AUTOSAR XML (schema 00048)
standard types defined: uint8, sint16, uint16, uint32, float32
package /Units
  9 x unit:
    Percent: display-name=%
    A: display-name=A
    Nm: display-name=Nm
    V: display-name=V
    W: display-name=W
    degC: display-name=degC
    s: display-name=s
    ms: display-name=ms
    Hz: display-name=Hz
package /Transformers
  data transformation set E2E
    data transformation DcdcOutputP1_Chain: data-transformation-kind=SYMMETRIC, execute-despite-data-unavailability=true, transformer-chain=[ComBased, DcdcOutputP1_E2E]
    data transformation DcdcThermalP2_Chain: data-transformation-kind=SYMMETRIC, execute-despite-data-unavailability=true, transformer-chain=[ComBased, DcdcThermalP2_E2E]
    data transformation DcdcPowerP5_Chain: data-transformation-kind=SYMMETRIC, execute-despite-data-unavailability=true, transformer-chain=[ComBased, DcdcPowerP5_E2E]
    4 x transformation technology, all with buffer-properties={header-length=0, in-place=true}, version=1.0.0:
      ComBased: protocol=COMBased, transformer-class=SERIALIZER
      DcdcOutputP1_E2E: needs-original-data=false, protocol=E2E, end-to-end-transformation-description{counter-offset=8, crc-offset=0, data-id-mode=ALL-16-BIT, max-delta-counter=1, max-no-new-or-repeated-data=15, profile-name=PROFILE_01, sync-counter-init=0}, transformer-class=SAFETY
      DcdcThermalP2_E2E: needs-original-data=false, protocol=E2E, end-to-end-transformation-description{max-delta-counter=1, max-no-new-or-repeated-data=15, offset=0, profile-name=PROFILE_02, sync-counter-init=0}, transformer-class=SAFETY
      DcdcPowerP5_E2E: needs-original-data=false, protocol=E2E, end-to-end-transformation-description{max-delta-counter=1, offset=0, profile-name=PROFILE_05}, transformer-class=SAFETY
package /SecOC
  secure communication props set Profile1
    secure communication authentication props Aes128Cmac24: auth-algorithm=CMAC/AES-128, auth-info-tx-length=24
    secure communication freshness props FreshnessCounter8: freshness-value-length=8, freshness-value-tx-length=8
package /Pdus
  pdu DcdcRail: length=4, contained-i-pdu-props={collection-semantics=LAST-IS-BEST, header-id-short-header=0x100001, trigger=ALWAYS}, transmission-mode-true-timing=cyclic-timing=time-period=0.06, unused-bit-pattern=255  # Contained: the 12 V rail.
    signal OutputVoltage: start 0, 16 bit, little-endian, data-type-policy=OVERRIDE, i-signal-type=PRIMITIVE, base-type=uint16, compu {phys=raw*0.01 for raw 0..65535; unit V}, range phys 0..655.35 V, unit=V, transfer-property=PENDING
    signal OutputCurrent: start 16, 16 bit, little-endian, data-type-policy=OVERRIDE, i-signal-type=PRIMITIVE, base-type=uint16, compu {phys=raw*0.1 for raw 0..65535; unit A}, range phys 0..6553.5 A, unit=A, transfer-property=PENDING
  pdu DcdcInput: length=4, contained-i-pdu-props={collection-semantics=LAST-IS-BEST, header-id-short-header=0x100002, trigger=ALWAYS}, transmission-mode-true-timing=cyclic-timing={time-offset=0.02, time-period=0.06}, unused-bit-pattern=255  # Contained: the pack side.
    signal InputCurrent: start 0, 16 bit, little-endian, data-type-policy=OVERRIDE, i-signal-type=PRIMITIVE, base-type=uint16, compu {phys=raw*0.01 for raw 0..65535; unit A}, range phys 0..655.35 A, unit=A, transfer-property=PENDING
    signal InputVoltage: start 16, 16 bit, little-endian, data-type-policy=OVERRIDE, i-signal-type=PRIMITIVE, base-type=uint16, compu {phys=raw*0.1 for raw 0..65534, 65535=Unknown; unit V}, range phys 0..6553.4 V, unit=V, transfer-property=PENDING
  pdu DcdcHealth: length=4, contained-i-pdu-props={collection-semantics=LAST-IS-BEST, header-id-short-header=0x100003, trigger=ALWAYS}, transmission-mode-true-timing=cyclic-timing={time-offset=0.04, time-period=0.06}, unused-bit-pattern=255  # Contained: temperature, state and uptime.
    signal Temperature: start 0, 8 bit, little-endian, data-type-policy=OVERRIDE, i-signal-type=PRIMITIVE, base-type=uint8, compu {phys=raw-40 for raw 0..255; unit degC}, range phys -40..215 degC, unit=degC, transfer-property=PENDING
    signal DcdcState: start 8, 8 bit, little-endian, data-type-policy=OVERRIDE, i-signal-type=PRIMITIVE, base-type=uint8, compu {0=Idle, 1=Converting, 2=Derating}, transfer-property=PENDING  # Idle: no pack current. Converting. Derating: above 70 degC.
    signal UptimeS: start 16, 16 bit, little-endian, data-type-policy=OVERRIDE, i-signal-type=PRIMITIVE, base-type=uint16, compu {phys=raw for raw 0..65535; unit s}, range phys 0..65535 s, unit=s, transfer-property=PENDING  # Seconds since boot, wrapping.
  pdu DcdcMuxStatic: length=8, unused-bit-pattern=255  # Static part of DcdcMux.
    signal DcdcState: start 8, 8 bit, little-endian, data-type-policy=OVERRIDE, i-signal-type=PRIMITIVE, base-type=uint8, compu {0=Idle, 1=Converting, 2=Derating}, transfer-property=PENDING  # Idle: no pack current. Converting. Derating: above 70 degC.
    signal OutputVoltage: start 16, 16 bit, little-endian, data-type-policy=OVERRIDE, i-signal-type=PRIMITIVE, base-type=uint16, compu {phys=raw*0.01 for raw 0..65535; unit V}, range phys 0..655.35 V, unit=V, transfer-property=PENDING
  pdu DcdcMuxCurrents: length=8, transmission-mode-true-timing=cyclic-timing=time-period=0.1, unused-bit-pattern=255  # DcdcMux dynamic part, selector 0.
    signal DcdcMuxSelector: start 0, 8 bit, little-endian, data-type-policy=OVERRIDE, i-signal-type=PRIMITIVE, base-type=uint8, compu {0=Currents, 1=Limits}, transfer-property=PENDING  # Selects the dynamic part.
    signal OutputCurrent: start 32, 16 bit, little-endian, data-type-policy=OVERRIDE, i-signal-type=PRIMITIVE, base-type=uint16, compu {phys=raw*0.1 for raw 0..65535; unit A}, range phys 0..6553.5 A, unit=A, transfer-property=PENDING
    signal InputCurrent: start 48, 16 bit, little-endian, data-type-policy=OVERRIDE, i-signal-type=PRIMITIVE, base-type=uint16, compu {phys=raw*0.01 for raw 0..65535; unit A}, range phys 0..655.35 A, unit=A, transfer-property=PENDING
  pdu DcdcMuxLimits: length=8, transmission-mode-true-timing=cyclic-timing={time-offset=0.05, time-period=0.1}, unused-bit-pattern=255  # DcdcMux dynamic part, selector 1.
    signal DcdcMuxSelector: start 0, 8 bit, little-endian, data-type-policy=OVERRIDE, i-signal-type=PRIMITIVE, base-type=uint8, compu {0=Currents, 1=Limits}, transfer-property=PENDING  # Selects the dynamic part.
    signal AuxCurrentLimit: start 32, 16 bit, little-endian, data-type-policy=OVERRIDE, i-signal-type=PRIMITIVE, base-type=uint16, compu {phys=raw*0.01 for raw 0..65535; unit A}, range phys 0..655.35 A, unit=A, transfer-property=PENDING
    signal SetpointVoltage: start 48, 16 bit, little-endian, data-type-policy=OVERRIDE, i-signal-type=PRIMITIVE, base-type=uint16, compu {phys=raw*0.01 for raw 0..65535; unit V}, range phys 0..655.35 V, unit=V, transfer-property=PENDING
  pdu DcdcSecuredPayload: length=4, transmission-mode-true-timing=cyclic-timing=time-period=0.1, unused-bit-pattern=255  # Authentic PDU of DcdcSecured.
    signal OutputVoltage: start 0, 16 bit, little-endian, data-type-policy=OVERRIDE, i-signal-type=PRIMITIVE, base-type=uint16, compu {phys=raw*0.01 for raw 0..65535; unit V}, range phys 0..655.35 V, unit=V, transfer-property=PENDING
    signal InputCurrent: start 16, 16 bit, little-endian, data-type-policy=OVERRIDE, i-signal-type=PRIMITIVE, base-type=uint16, compu {phys=raw*0.01 for raw 0..65535; unit A}, range phys 0..655.35 A, unit=A, transfer-property=PENDING
  dcm i pdu UdsRequestSdu: length=1026, diag-pdu-type=DIAG-REQUEST  # Physically addressed diagnostic requests.
  dcm i pdu UdsFunctionalRequestSdu: length=1026, diag-pdu-type=DIAG-REQUEST  # Functionally addressed diagnostic requests (single frames).
  dcm i pdu UdsResponseSdu: length=1026, diag-pdu-type=DIAG-RESPONSE  # Diagnostic responses.
package /Signals/DcdcOutputP1
  i signal group DcdcOutputP1_E2E: com-based-signal-group-transformations=DcdcOutputP1_Chain, i-signal=[DcdcOutputP1/CRC, DcdcOutputP1/Counter, DcdcOutputP1/DcdcState, DcdcOutputP1/OutputVoltage, DcdcOutputP1/OutputCurrent, DcdcOutputP1/InputCurrent], system-signal-group=DcdcOutputP1_E2E, end-to-end-transformation-i-signal-props{transformer=DcdcOutputP1_E2E, data-ids=0x0310, data-length=64}
package /Signals/DcdcThermalP2
  i signal group DcdcThermalP2_E2E:
    com-based-signal-group-transformations=DcdcThermalP2_Chain
    i-signal=[DcdcThermalP2/CRC, DcdcThermalP2/Counter, DcdcThermalP2/Temperature, DcdcThermalP2/DerateActive, DcdcThermalP2/AuxCurrentLimit]
    system-signal-group=DcdcThermalP2_E2E
    end-to-end-transformation-i-signal-props{transformer=DcdcThermalP2_E2E, data-ids=[0x30, 0x31, 0x32, 0x33, 0x34, 0x35, 0x36, 0x37, 0x38, 0x39, 0x3A, 0x3B, 0x3C, 0x3D, 0x3E, 0x3F], data-length=64}
package /Signals/DcdcPowerP5
  i signal group DcdcPowerP5_E2E: com-based-signal-group-transformations=DcdcPowerP5_Chain, i-signal=[DcdcPowerP5/CRC, DcdcPowerP5/Counter, OutputPower, DcdcPowerP5/InputVoltage, DcdcPowerP5/SetpointVoltage], system-signal-group=DcdcPowerP5_E2E, end-to-end-transformation-i-signal-props{transformer=DcdcPowerP5_E2E, data-ids=0x0312, data-length=64}
package /PduGroups
  8 x i signal i pdu group:
    BMS_Rx: communication-direction=IN, i-signal-i-pdus=[VCU_Command, DCDC_Status]
    BMS_Tx: communication-direction=OUT, i-signal-i-pdus=[BMS_Status, BMS_Limits, BMS_CellVoltages]
    DCDC_Rx: communication-direction=IN, i-signal-i-pdus=[VCU_Command, BMS_Status, BMS_Limits]
    DCDC_Tx: communication-direction=OUT
      i-signal-i-pdus:
        DCDC_Status
        DcdcOutputP1
        DcdcThermalP2
        DcdcPowerP5
        DcdcRail
        DcdcInput
        DcdcHealth
        DcdcMuxStatic
        DcdcMuxCurrents
        DcdcMuxLimits
        DcdcSecuredPayload
    SIG_Tx: communication-direction=OUT, i-signal-i-pdus=Waveform
    Tester_Rx: communication-direction=IN
      i-signal-i-pdus:
        DcdcOutputP1
        DcdcThermalP2
        DcdcPowerP5
        DcdcRail
        DcdcInput
        DcdcHealth
        DcdcMuxStatic
        DcdcMuxCurrents
        DcdcMuxLimits
        DcdcSecuredPayload
    VCU_Rx: communication-direction=IN, i-signal-i-pdus=[BMS_Status, BMS_Limits, BMS_CellVoltages, DCDC_Status, Waveform]
    VCU_Tx: communication-direction=OUT, i-signal-i-pdus=VCU_Command
package /Ecus
  5 x ecu instance:
    VCU: associated-com-i-pdu-group=[VCU_Rx, VCU_Tx]  # Vehicle control unit. Commands the operating mode and carries the bus heartbeat.
      can communication controller VCU_CanController
      can communication connector VCU_CanConnector: comm-controller=VCU_CanController
    BMS: associated-com-i-pdu-group=[BMS_Rx, BMS_Tx]  # Battery management system. Reports pack state and publishes the current limits the DC-DC must respect.
      can communication controller BMS_CanController
      can communication connector BMS_CanConnector: comm-controller=BMS_CanController
    DCDC: associated-com-i-pdu-group=[DCDC_Rx, DCDC_Tx]  # DC-DC converter. Steps the high-voltage pack down to the 12 V rail, within the BMS current limit. AUTOSAR PDUs (E2E, container, multiplexed, secured), UDS on CanTp, XCP on CAN. SOME/IP DcdcService and DoIP on BenchEth.
      can communication controller DCDC_CanController
      ethernet communication controller DCDC_EthController
      can communication connector DCDC_CanConnector: comm-controller=DCDC_CanController
      ethernet communication connector DCDC_EthConnector: comm-controller=DCDC_EthController
    SIG: associated-com-i-pdu-group=SIG_Tx
      can communication controller SIG_CanController
      can communication connector SIG_CanConnector: comm-controller=SIG_CanController
    Tester: associated-com-i-pdu-group=Tester_Rx  # Diagnostic tester, XCP master and logger on the bus.
      can communication controller Tester_CanController
      can communication connector Tester_CanConnector: comm-controller=Tester_CanController
package /Communication
  can cluster CanFull: baudrate=500000, protocol-name=CAN, protocol-version=2.0  # The can-full bench bus: classic CAN, 500 kbit/s, 11-bit identifiers.
    can physical channel CanFullChannel: comm-connectors=[VCU_CanConnector, BMS_CanConnector, DCDC_CanConnector, SIG_CanConnector, Tester_CanConnector]
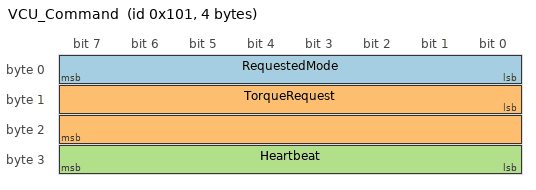
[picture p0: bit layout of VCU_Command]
      frame VCU_Command: id 0x101, from VCU, to BMS DCDC, frame-length=4, can-addressing-mode=STANDARD, can-frame-rx-behavior=CAN-20, can-frame-tx-behavior=CAN-20  # Operating mode request and heartbeat. The BMS and DC-DC both follow the commanded mode.
        pdu VCU_Command: length=4, transmission-mode-true-timing=cyclic-timing=time-period=0.1, unused-bit-pattern=0  # Operating mode request and heartbeat. The BMS and DC-DC both follow the commanded mode.
          signal RequestedMode: start 0, 8 bit, little-endian, data-type-policy=OVERRIDE, i-signal-type=PRIMITIVE, base-type=uint8, compu {0=Standby, 1=Drive, 2=Charge, 3=Fault}, transfer-property=PENDING
          signal TorqueRequest: start 8, 16 bit, little-endian, data-type-policy=OVERRIDE, i-signal-type=PRIMITIVE, base-type=sint16, compu {phys=raw*0.1 for raw -10000..10000; unit Nm}, range phys -1000..1000 Nm, unit=Nm, transfer-property=PENDING  # Positive is drive, negative is regenerative braking.
          signal Heartbeat: start 24, 8 bit, little-endian, data-type-policy=OVERRIDE, i-signal-type=PRIMITIVE, base-type=uint8, compu {phys=raw for raw 0..255}, range phys 0..255, transfer-property=PENDING
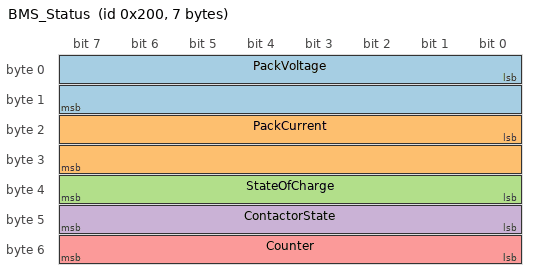
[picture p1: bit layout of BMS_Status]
      frame BMS_Status: id 0x200, from BMS, to VCU DCDC, frame-length=7, can-addressing-mode=STANDARD, can-frame-rx-behavior=CAN-20, can-frame-tx-behavior=CAN-20  # Pack-level measurements and contactor state.
        pdu BMS_Status: length=7, transmission-mode-true-timing=cyclic-timing=time-period=0.1, unused-bit-pattern=0  # Pack-level measurements and contactor state.
          signal PackVoltage: start 0, 16 bit, little-endian, data-type-policy=OVERRIDE, i-signal-type=PRIMITIVE, base-type=uint16, compu {phys=raw*0.1 for raw 0..10000; unit V}, range phys 0..1000 V, unit=V, transfer-property=PENDING
          signal PackCurrent: start 16, 16 bit, little-endian, data-type-policy=OVERRIDE, i-signal-type=PRIMITIVE, base-type=sint16, compu {phys=raw*0.1 for raw -10000..10000; unit A}, range phys -1000..1000 A, unit=A, transfer-property=PENDING  # Positive is discharge, negative is charge.
          signal StateOfCharge: start 32, 8 bit, little-endian, data-type-policy=OVERRIDE, i-signal-type=PRIMITIVE, base-type=uint8, compu {phys=raw*0.5 for raw 0..200; unit %}, range phys 0..100 %, unit=%, transfer-property=PENDING
          signal ContactorState: start 40, 8 bit, little-endian, data-type-policy=OVERRIDE, i-signal-type=PRIMITIVE, base-type=uint8, compu {0=Open, 1=Precharge, 2=Closed, 3=Fault}, transfer-property=PENDING
          signal Counter: start 48, 8 bit, little-endian, data-type-policy=OVERRIDE, i-signal-type=PRIMITIVE, base-type=uint8, compu {phys=raw for raw 0..255}, range phys 0..255, transfer-property=PENDING
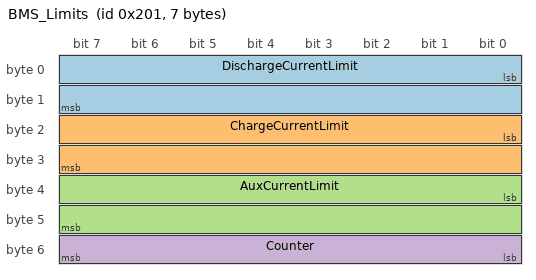
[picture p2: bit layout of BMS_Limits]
      frame BMS_Limits: id 0x201, from BMS, to VCU DCDC, frame-length=7, can-addressing-mode=STANDARD, can-frame-rx-behavior=CAN-20, can-frame-tx-behavior=CAN-20  # The current envelope the pack allows right now. AuxCurrentLimit bounds what the DC-DC may draw from the pack.
        pdu BMS_Limits: length=7, transmission-mode-true-timing=cyclic-timing=time-period=0.1, unused-bit-pattern=0  # The current envelope the pack allows right now. AuxCurrentLimit bounds what the DC-DC may draw from the pack.
          signal DischargeCurrentLimit: start 0, 16 bit, little-endian, data-type-policy=OVERRIDE, i-signal-type=PRIMITIVE, base-type=uint16, compu {phys=raw*0.01 for raw 0..65535; unit A}, range phys 0..655.35 A, unit=A, transfer-property=PENDING  # Pack-level ceiling for traction draw.
          signal ChargeCurrentLimit: start 16, 16 bit, little-endian, data-type-policy=OVERRIDE, i-signal-type=PRIMITIVE, base-type=uint16, compu {phys=raw*0.01 for raw 0..65535; unit A}, range phys 0..655.35 A, unit=A, transfer-property=PENDING
          signal AuxCurrentLimit: start 32, 16 bit, little-endian, data-type-policy=OVERRIDE, i-signal-type=PRIMITIVE, base-type=uint16, compu {phys=raw*0.01 for raw 0..65535; unit A}, range phys 0..655.35 A, unit=A, transfer-property=PENDING  # Pack current the DC-DC converter may draw. The BMS reduces it while charging.
          signal Counter: start 48, 8 bit, little-endian, data-type-policy=OVERRIDE, i-signal-type=PRIMITIVE, base-type=uint8, compu {phys=raw for raw 0..255}, range phys 0..255, transfer-property=PENDING
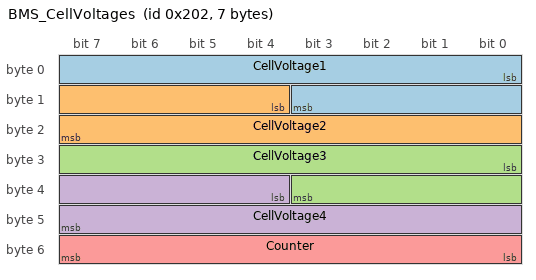
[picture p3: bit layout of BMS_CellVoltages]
      frame BMS_CellVoltages: id 0x202, from BMS, to VCU, frame-length=7, can-addressing-mode=STANDARD, can-frame-rx-behavior=CAN-20, can-frame-tx-behavior=CAN-20  # Per-cell voltages. Four cells, one frame, no multiplexing.
        pdu BMS_CellVoltages: length=7, transmission-mode-true-timing=cyclic-timing=time-period=0.5, unused-bit-pattern=0  # Per-cell voltages. Four cells, one frame, no multiplexing.
          signal CellVoltage1: start 0, 12 bit, little-endian, data-type-policy=OVERRIDE, i-signal-type=PRIMITIVE, base-type=uint16, compu {phys=raw*0.001+2 for raw 0..4095; unit V}, range phys 2..6.095 V, unit=V, transfer-property=PENDING
          signal CellVoltage2: start 12, 12 bit, little-endian, data-type-policy=OVERRIDE, i-signal-type=PRIMITIVE, base-type=uint16, compu {phys=raw*0.001+2 for raw 0..4095; unit V}, range phys 2..6.095 V, unit=V, transfer-property=PENDING
          signal CellVoltage3: start 24, 12 bit, little-endian, data-type-policy=OVERRIDE, i-signal-type=PRIMITIVE, base-type=uint16, compu {phys=raw*0.001+2 for raw 0..4095; unit V}, range phys 2..6.095 V, unit=V, transfer-property=PENDING
          signal CellVoltage4: start 36, 12 bit, little-endian, data-type-policy=OVERRIDE, i-signal-type=PRIMITIVE, base-type=uint16, compu {phys=raw*0.001+2 for raw 0..4095; unit V}, range phys 2..6.095 V, unit=V, transfer-property=PENDING
          signal Counter: start 48, 8 bit, little-endian, data-type-policy=OVERRIDE, i-signal-type=PRIMITIVE, base-type=uint8, compu {phys=raw for raw 0..255}, range phys 0..255, transfer-property=PENDING
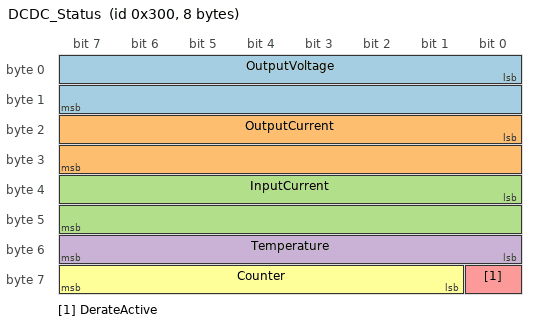
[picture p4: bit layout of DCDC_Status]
      frame DCDC_Status: id 0x300, from DCDC, to VCU BMS, frame-length=8, can-addressing-mode=STANDARD, can-frame-rx-behavior=CAN-20, can-frame-tx-behavior=CAN-20  # DC-DC converter state. InputCurrent is drawn from the pack and must stay within BMS_Limits.AuxCurrentLimit.
        pdu DCDC_Status: length=8, transmission-mode-true-timing=cyclic-timing=time-period=0.05, unused-bit-pattern=0  # DC-DC converter state. InputCurrent is drawn from the pack and must stay within BMS_Limits.AuxCurrentLimit.
          signal OutputVoltage: start 0, 16 bit, little-endian, data-type-policy=OVERRIDE, i-signal-type=PRIMITIVE, base-type=uint16, compu {phys=raw*0.01 for raw 0..65535; unit V}, range phys 0..655.35 V, unit=V, transfer-property=PENDING
          signal OutputCurrent: start 16, 16 bit, little-endian, data-type-policy=OVERRIDE, i-signal-type=PRIMITIVE, base-type=uint16, compu {phys=raw*0.1 for raw 0..65535; unit A}, range phys 0..6553.5 A, unit=A, transfer-property=PENDING
          signal InputCurrent: start 32, 16 bit, little-endian, data-type-policy=OVERRIDE, i-signal-type=PRIMITIVE, base-type=uint16, compu {phys=raw*0.01 for raw 0..65535; unit A}, range phys 0..655.35 A, unit=A, transfer-property=PENDING  # Current drawn from the high-voltage pack.
          signal Temperature: start 48, 8 bit, little-endian, data-type-policy=OVERRIDE, i-signal-type=PRIMITIVE, base-type=uint8, compu {phys=raw-40 for raw 0..255; unit degC}, range phys -40..215 degC, unit=degC, transfer-property=PENDING
          signal DerateActive: start 56, 1 bit, little-endian, data-type-policy=OVERRIDE, i-signal-type=PRIMITIVE, base-type=uint8, compu {0=Inactive, 1=Active}, transfer-property=PENDING  # Set when the converter is limiting output because of temperature.
          signal Counter: start 57, 7 bit, little-endian, data-type-policy=OVERRIDE, i-signal-type=PRIMITIVE, base-type=uint8, compu {phys=raw for raw 0..127}, range phys 0..127, transfer-property=PENDING
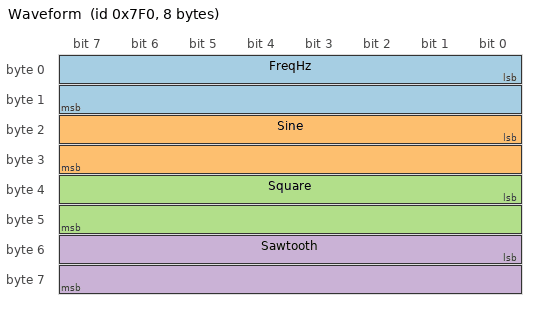
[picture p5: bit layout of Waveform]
      frame Waveform: id 0x7F0, from SIG, to VCU, frame-length=8, can-addressing-mode=STANDARD, can-frame-rx-behavior=CAN-20, can-frame-tx-behavior=CAN-20  # Signal generator: one phase, chirped 1 to 100 Hz over 20 s, as sine, square and sawtooth. Lowest-priority ID on the bus.
        pdu Waveform: length=8, transmission-mode-true-timing=cyclic-timing=time-period=0.002, unused-bit-pattern=0  # Signal generator: one phase, chirped 1 to 100 Hz over 20 s, as sine, square and sawtooth. Lowest-priority ID on the bus.
          signal FreqHz: start 0, 16 bit, little-endian, data-type-policy=OVERRIDE, i-signal-type=PRIMITIVE, base-type=uint16, compu {phys=raw*0.01 for raw 0..65535; unit Hz}, range phys 0..655.35 Hz, unit=Hz, transfer-property=PENDING
          signal Sine: start 16, 16 bit, little-endian, data-type-policy=OVERRIDE, i-signal-type=PRIMITIVE, base-type=sint16, compu {phys=raw*0.001 for raw -1000..1000}, range phys -1..1, transfer-property=PENDING
          signal Square: start 32, 16 bit, little-endian, data-type-policy=OVERRIDE, i-signal-type=PRIMITIVE, base-type=sint16, compu {phys=raw*0.001 for raw -1000..1000}, range phys -1..1, transfer-property=PENDING
          signal Sawtooth: start 48, 16 bit, little-endian, data-type-policy=OVERRIDE, i-signal-type=PRIMITIVE, base-type=sint16, compu {phys=raw*0.001 for raw -1000..1000}, range phys -1..1, transfer-property=PENDING
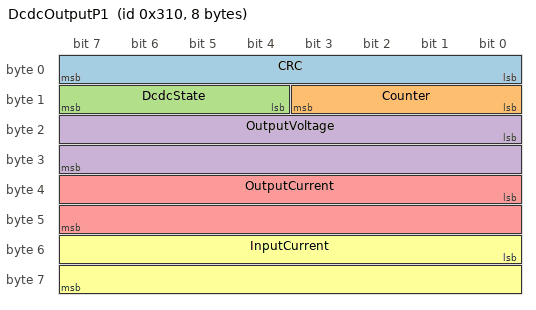
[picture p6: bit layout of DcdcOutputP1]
      frame DcdcOutputP1: id 0x310, from DCDC, to Tester, frame-length=8, can-addressing-mode=STANDARD, can-frame-rx-behavior=CAN-20, can-frame-tx-behavior=CAN-20  # Rail output and pack current, E2E profile 1.
        pdu DcdcOutputP1: length=8, transmission-mode-true-timing=cyclic-timing=time-period=0.02, unused-bit-pattern=255  # Rail output and pack current, E2E profile 1.
          signal CRC: start 0, 8 bit, little-endian, data-type-policy=OVERRIDE, i-signal-type=PRIMITIVE, base-type=uint8, transfer-property=PENDING  # E2E CRC
          signal Counter: start 8, 4 bit, little-endian, data-type-policy=OVERRIDE, i-signal-type=PRIMITIVE, base-type=uint8, transfer-property=PENDING  # E2E counter
          signal DcdcState: start 12, 4 bit, little-endian, data-type-policy=OVERRIDE, i-signal-type=PRIMITIVE, base-type=uint8, compu {0=Idle, 1=Converting, 2=Derating}, transfer-property=PENDING  # Idle: no pack current. Converting. Derating: above 70 degC.
          signal OutputVoltage: start 16, 16 bit, little-endian, data-type-policy=OVERRIDE, i-signal-type=PRIMITIVE, base-type=uint16, compu {phys=raw*0.001 for raw 0..65535; unit V}, range phys 0..65.535 V, unit=V, transfer-property=PENDING
          signal OutputCurrent: start 32, 16 bit, little-endian, data-type-policy=OVERRIDE, i-signal-type=PRIMITIVE, base-type=uint16, compu {phys=raw*0.05 for raw 0..65535; unit A}, range phys 0..3276.75 A, unit=A, transfer-property=PENDING
          signal InputCurrent: start 48, 16 bit, little-endian, data-type-policy=OVERRIDE, i-signal-type=PRIMITIVE, base-type=uint16, compu {phys=raw*0.001 for raw 0..65535; unit A}, range phys 0..65.535 A, unit=A, transfer-property=PENDING  # Current drawn from the high-voltage pack.
          mapping DcdcOutputP1_E2E: i-signal-group=DcdcOutputP1_E2E
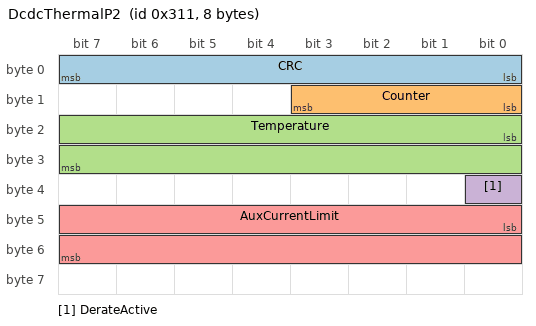
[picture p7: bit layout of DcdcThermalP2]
      frame DcdcThermalP2: id 0x311, from DCDC, to Tester, frame-length=8, can-addressing-mode=STANDARD, can-frame-rx-behavior=CAN-20, can-frame-tx-behavior=CAN-20  # Thermal state and the pack allowance, E2E profile 2.
        pdu DcdcThermalP2: length=8, transmission-mode-true-timing=cyclic-timing=time-period=0.05, unused-bit-pattern=255  # Thermal state and the pack allowance, E2E profile 2.
          signal CRC: start 0, 8 bit, little-endian, data-type-policy=OVERRIDE, i-signal-type=PRIMITIVE, base-type=uint8, transfer-property=PENDING  # E2E CRC
          signal Counter: start 8, 4 bit, little-endian, data-type-policy=OVERRIDE, i-signal-type=PRIMITIVE, base-type=uint8, transfer-property=PENDING  # E2E counter
          signal Temperature: start 16, 16 bit, little-endian, data-type-policy=OVERRIDE, i-signal-type=PRIMITIVE, base-type=sint16, compu {phys=raw*0.1 for raw -400..2150; unit degC}, range phys -40..215 degC, unit=degC, transfer-property=PENDING
          signal DerateActive: start 32, 1 bit, little-endian, data-type-policy=OVERRIDE, i-signal-type=PRIMITIVE, base-type=uint8, compu {0=Inactive, 1=Active}, transfer-property=PENDING  # Set while the converter limits its output for temperature.
          signal AuxCurrentLimit: start 40, 16 bit, little-endian, data-type-policy=OVERRIDE, i-signal-type=PRIMITIVE, base-type=uint16, compu {phys=raw*0.01 for raw 0..65535; unit A}, range phys 0..655.35 A, unit=A, transfer-property=PENDING  # BMS_Limits.AuxCurrentLimit as the converter follows it.
          mapping DcdcThermalP2_E2E: i-signal-group=DcdcThermalP2_E2E
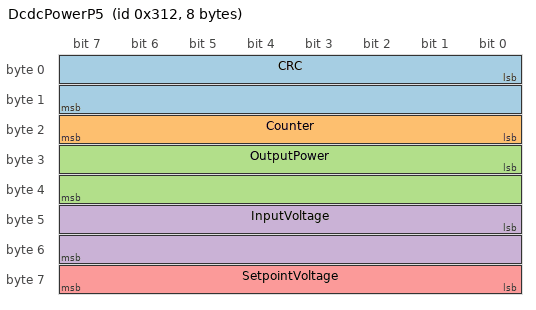
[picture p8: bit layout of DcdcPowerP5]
      frame DcdcPowerP5: id 0x312, from DCDC, to Tester, frame-length=8, can-addressing-mode=STANDARD, can-frame-rx-behavior=CAN-20, can-frame-tx-behavior=CAN-20  # Power, pack voltage and setpoint, E2E profile 5.
        pdu DcdcPowerP5: length=8, transmission-mode-true-timing=cyclic-timing=time-period=0.02, unused-bit-pattern=255  # Power, pack voltage and setpoint, E2E profile 5.
          signal CRC: start 0, 16 bit, little-endian, data-type-policy=OVERRIDE, i-signal-type=PRIMITIVE, base-type=uint16, transfer-property=PENDING  # E2E CRC
          signal Counter: start 16, 8 bit, little-endian, data-type-policy=OVERRIDE, i-signal-type=PRIMITIVE, base-type=uint8, transfer-property=PENDING  # E2E counter
          signal OutputPower: start 24, 16 bit, little-endian, data-type-policy=OVERRIDE, i-signal-type=PRIMITIVE, base-type=uint16, compu {phys=raw for raw 0..65535; unit W}, range phys 0..65535 W, unit=W, transfer-property=PENDING  # Rail voltage times rail current.
          signal InputVoltage: start 40, 16 bit, little-endian, data-type-policy=OVERRIDE, i-signal-type=PRIMITIVE, base-type=uint16, compu {phys=raw*0.1 for raw 0..65534, 65535=Unknown; unit V}, range phys 0..6553.4 V, unit=V, transfer-property=PENDING  # Pack voltage from BMS_Status; Unknown when none is fresh.
          signal SetpointVoltage: start 56, 8 bit, little-endian, data-type-policy=OVERRIDE, i-signal-type=PRIMITIVE, base-type=uint8, compu {phys=raw*0.1 for raw 0..255; unit V}, range phys 0..25.5 V, unit=V, transfer-property=PENDING  # Output voltage the converter regulates to.
          mapping DcdcPowerP5_E2E: i-signal-group=DcdcPowerP5_E2E
      frame DcdcContainer: id 0x313, from DCDC, to Tester, frame-length=8, can-addressing-mode=STANDARD, can-frame-rx-behavior=CAN-20, can-frame-tx-behavior=CAN-20  # Dynamic container, short headers: one contained PDU per frame.
        container i pdu DcdcContainer: length=8, contained-pdu-triggering=[PT_DcdcRail, PT_DcdcInput, PT_DcdcHealth], container-trigger=FIRST-CONTAINED-TRIGGER, header-type=SHORT-HEADER, unused-bit-pattern=255  # Dynamic container, short headers: one contained PDU per frame.
      frame DcdcMux: id 0x314, from DCDC, to Tester, frame-length=8, can-addressing-mode=STANDARD, can-frame-rx-behavior=CAN-20, can-frame-tx-behavior=CAN-20  # Multiplexed: state and voltage always, currents and limits in turn.
        multiplexed i pdu DcdcMux:  # Multiplexed: state and voltage always, currents and limits in turn.
          length=8
          dynamic-part{segment-positions=[{segment-byte-order=little-endian, segment-length=8, segment-position=0}, {segment-byte-order=little-endian, segment-length=32, segment-position=32}], dynamic-part-alternatives=[{i-pdu=DcdcMuxCurrents, initial-dynamic-part=true, selector-field-code=0}, {i-pdu=DcdcMuxLimits, initial-dynamic-part=false, selector-field-code=1}]}
          selector-field-byte-order=little-endian
          selector-field-length=8
          selector-field-start-position=0
          static-part{segment-position{segment-byte-order=little-endian, segment-length=24, segment-position=8}, i-pdu=DcdcMuxStatic}
          trigger-mode=DYNAMIC-PART-TRIGGER
          unused-bit-pattern=255
      frame DcdcSecured: id 0x315, from DCDC, to Tester, frame-length=8, can-addressing-mode=STANDARD, can-frame-rx-behavior=CAN-20, can-frame-tx-behavior=CAN-20  # SecOC profile 1 (24Bit-CMAC-8Bit-FV): payload, 8-bit freshness, 24-bit AES-128 CMAC.
        secured i pdu DcdcSecured: length=8, authentication-props=Aes128Cmac24, freshness-props=FreshnessCounter8, payload=PT_DcdcSecuredPayload, secure-communication-props=data-id=0x0315  # SecOC profile 1 (24Bit-CMAC-8Bit-FV): payload, 8-bit freshness, 24-bit AES-128 CMAC.
      frame UdsRequest: id 0x7E0, from Tester, to DCDC, frame-length=8, can-addressing-mode=STANDARD, can-frame-rx-behavior=CAN-20, can-frame-tx-behavior=CAN-20  # ISO-TP frames of physical requests, and the tester's flow control.
        n pdu UdsRequest: length=8  # ISO-TP frames of physical requests, and the tester's flow control.
      frame UdsFunctionalRequest: id 0x7DF, from Tester, to DCDC, frame-length=8, can-addressing-mode=STANDARD, can-frame-rx-behavior=CAN-20, can-frame-tx-behavior=CAN-20  # ISO-TP single frames of functional requests.
        n pdu UdsFunctionalRequest: length=8  # ISO-TP single frames of functional requests.
      frame UdsResponse: id 0x7E8, from DCDC, to Tester, frame-length=8, can-addressing-mode=STANDARD, can-frame-rx-behavior=CAN-20, can-frame-tx-behavior=CAN-20  # ISO-TP frames of responses, and the DC-DC's flow control.
        n pdu UdsResponse: length=8  # ISO-TP frames of responses, and the DC-DC's flow control.
      frame XcpCro: id 0x6F0, from Tester, to DCDC, frame-length=8, can-addressing-mode=STANDARD, can-frame-rx-behavior=CAN-20, can-frame-tx-behavior=CAN-20  # XCP master to slave.
        general purpose i pdu XcpCro: category=XCP, length=8  # XCP master to slave.
      frame XcpDto: id 0x6F1, from DCDC, to Tester, frame-length=8, can-addressing-mode=STANDARD, can-frame-rx-behavior=CAN-20, can-frame-tx-behavior=CAN-20  # XCP slave to master: responses, events, DAQ.
        general purpose i pdu XcpDto: category=XCP, length=8  # XCP slave to master: responses, events, DAQ.
      pdu triggering PT_DcdcRail: pdu=DcdcRail, from DCDC, to Tester
      pdu triggering PT_DcdcInput: pdu=DcdcInput, from DCDC, to Tester
      pdu triggering PT_DcdcHealth: pdu=DcdcHealth, from DCDC, to Tester
      pdu triggering PT_DcdcMuxStatic: pdu=DcdcMuxStatic, from DCDC, to Tester
      pdu triggering PT_DcdcMuxCurrents: pdu=DcdcMuxCurrents, from DCDC, to Tester
      pdu triggering PT_DcdcMuxLimits: pdu=DcdcMuxLimits, from DCDC, to Tester
      pdu triggering PT_DcdcSecuredPayload: pdu=DcdcSecuredPayload, from DCDC, to Tester
      pdu triggering PT_UdsRequestSdu: pdu=UdsRequestSdu, from Tester, to DCDC
      pdu triggering PT_UdsFunctionalRequestSdu: pdu=UdsFunctionalRequestSdu, from Tester, to DCDC
      pdu triggering PT_UdsResponseSdu: pdu=UdsResponseSdu, from DCDC, to Tester
  ethernet cluster BenchEth  # The bench Ethernet: the DC-DC at 10.1.1.75/24, SOME/IP on UDP only, SD on UDP 30490 and multicast group 224.224.224.245.
    ethernet physical channel BenchEthCh: comm-connectors=DCDC_EthConnector
      network endpoint NE_Dcdc: network-endpoint-addresses=ipv-4-configuration={ipv-4-address=10.1.1.75, ipv-4-address-source=FIXED, network-mask=255.255.255.0}
      network endpoint NE_SdMulticast: network-endpoint-addresses=ipv-4-configuration={ipv-4-address=224.224.224.245, ipv-4-address-source=FIXED}
      so-ad-config:
        socket address SA_DcdcService: connector=DCDC_EthConnector
          application endpoint SA_DcdcService_AE: network-endpoint=NE_Dcdc, tp-configuration=udp-tp=udp-tp-port=port-number=30509
        socket address SA_Sd: multicast-connector=DCDC_EthConnector
          application endpoint SA_Sd_AE: network-endpoint=NE_SdMulticast, tp-configuration=udp-tp=udp-tp-port=port-number=30490
package /CanTp
  can tp config CanFullCanTp: communication-cluster=CanFull, tp-ecus=[DCDC, Tester]  # ISO 15765-2 normal addressing, as the DC-DC's UDS server runs it: block size 0, STmin 0, frames padded to 8 bytes (0xCC), N_As/N_Ar/N_Bs/N_Cr 1 s, half duplex.
    can tp channel UdsChannel: channel-id=0, channel-mode=HALF-DUPLEX-MODE
    can-tp-connection addressing-format=STANDARD, can-tp-channel=UdsChannel, data-pdu=UdsRequest, flow-control-pdu=UdsResponse, max-block-size=0, padding-activation=true, receiver=DCDC_TpNode, ta-type=PHYSICAL, timeout-bs=1, timeout-cr=1, tp-sdu=UdsRequestSdu, transmitter=Tester_TpNode:
      ident UdsPhysical
    can-tp-connection addressing-format=STANDARD, can-tp-channel=UdsChannel, data-pdu=UdsFunctionalRequest, max-block-size=0, padding-activation=true, receiver=DCDC_TpNode, ta-type=FUNCTIONAL, tp-sdu=UdsFunctionalRequestSdu, transmitter=Tester_TpNode:
      ident UdsFunctional
    can-tp-connection addressing-format=STANDARD, can-tp-channel=UdsChannel, data-pdu=UdsResponse, flow-control-pdu=UdsRequest, max-block-size=0, padding-activation=true, receiver=Tester_TpNode, ta-type=PHYSICAL, timeout-bs=1, timeout-cr=1, tp-sdu=UdsResponseSdu, transmitter=DCDC_TpNode:
      ident UdsResponse
    can tp node DCDC_TpNode: connector=DCDC_CanConnector, max-fc-wait=0, st-min=0, timeout-ar=1, timeout-as=1
    can tp node Tester_TpNode: connector=Tester_CanConnector, max-fc-wait=0, st-min=0, timeout-ar=1, timeout-as=1
package /DataTypes
  impl type DcdcStatusType: category=STRUCTURE  # 26 bytes. InputVoltage is NaN with no fresh BMS_Status; Counter is the DCDC_Status Counter of the same sample.
    8 x element, all with category=VALUE:
      OutputVoltage: base-type=float32, unit=V
      OutputCurrent: base-type=float32, unit=A
      InputVoltage: base-type=float32, unit=V
      InputCurrent: base-type=float32, unit=A
      Temperature: base-type=float32, unit=degC
      State: base-type=uint8, compu {0=Idle, 1=Converting, 2=Derating}
      Counter: base-type=uint8
      Uptime: base-type=uint32, unit=ms
  impl type SetpointType: category=VALUE, base-type=uint16, compu {phys=raw*0.01 for raw 0..65535; unit V}
package /ServiceInterfaces
  service interface DcdcService: major-version=1, minor-version=0
    events:
      data DcdcStatus: type=DcdcStatusType  # Cyclic, every 100 ms.
    field Setpoint: type=SetpointType, has-getter=true, has-notifier=true, has-setter=false  # Output voltage setpoint, UDS DID 0x0200. Written through UDS only, behind security access.
package /Deployments
  someip service interface deployment DcdcService_SomeIp: service-interface=DcdcService, service-interface-id=23040, service-interface-version={major-version=1, minor-version=0}
    someip event deployment DcdcStatus: event=DcdcStatus, event-id=32769, transport-protocol=UDP
    someip field deployment Setpoint: field=Setpoint
      get Setpoint_get: method-id=1, transport-protocol=UDP
      notifier Setpoint_notify: event-id=32770, transport-protocol=UDP
    someip event group Eventgroup1: event-group-id=1, event=[DcdcStatus, Setpoint_notify]
package /TransformationProps
  transformation props set SomeIpProps
    ap someip transformation props BigEndianNoLength: byte-order=big-endian, size-of-struct-length-field=0
  transformation props to service interface element mapping set DcdcServiceProps
    transformation props to service interface element mapping DcdcService: event=DcdcStatus, field=Setpoint, transformation-props=BigEndianNoLength
package /ServiceInstances
  service instance collection set Services
    provided service instance DcdcService_1: major-version=1, instance-identifier=1, local-unicast-addresss=SA_DcdcService_AE, minor-version=0, sd-server-timer-configs=DcdcSdServer, service-identifier=23040
      event handler Eventgroup1: event-group-identifier=1
  someip sd server service instance config DcdcSdServer: initial-offer-behavior={initial-delay-max-value=0.1, initial-delay-min-value=0.01, initial-repetitions-base-delay=0.1, initial-repetitions-max=3}, offer-cyclic-delay=1, request-response-delay={max-value=0.1, min-value=0}, service-offer-time-to-live=3
package /DoIp
  do ip tp config BenchEthDoIp: communication-cluster=BenchEth
    do ip logic address DCDC: address=4097
    do ip logic address Tester: address=3712
    do ip logic address Functional: address=58368
package /System
  system CanFull: category=SYSTEM_DESCRIPTION, container-i-pdu-header-byte-order=big-endian, system-version=1.0.0  # The zelos-examples can-full bench: the VCU and BMS nodes and the DC-DC of the combined image (nodes/full). bench.dbc plus the DC-DC's AUTOSAR PDUs, UDS and XCP, and its SOME/IP DcdcService on BenchEth. J1939 (genset.dbc) and CANopen (nodes/pdu/od/pdu.eds) on the same bus are described in their own files.
